# SN32F420 register map
Vendor: SONiX Technology Co., Ltd.; Series: SN32F420; File version: 1.00
CPU: CM0 r0p0, little endian, no MPU, no FPU, 2 interrupt priority bits
Registers are 32-bit, read-write, reset 0x0 unless marked. A register's access mark holds for its fields unless they carry their own. Offsets are from the block's base; [hi:lo] are bit positions; {n}, {i} and the like mark numbered series.

## SN_SYS1 — System Control Registers 1
Base 0x4005E000
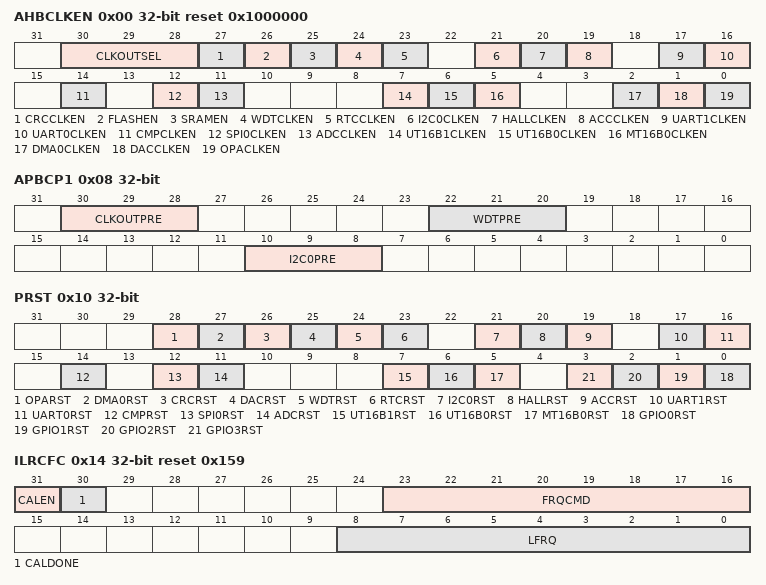
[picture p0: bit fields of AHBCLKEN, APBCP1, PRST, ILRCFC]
0x00 AHBCLKEN reset 0x1000000 — Offset:0x00 AHB Clock Enable register
  [30:28] CLKOUTSEL — Clock output source selection
    0=000b (Disable); 1=001b (ILRC); 4=100b (HCLK); 5=101b (IHRC); 7=111b (PLL output)
  [27] CRCCLKEN — Enable AHB clock for CRC
    0=Disable CRC clock; 1=Enable CRC clock
  [26] FLASHEN — Enable Flash clock during sleep mode
    0=Disable Flash clock during sleep mode; 1=Enable Flash clock during sleep mode
  [25] SRAMEN — Enable SRAM clock during sleep mode
    0=Disable SRAM clock during sleep mode; 1=Enable SRAM clock during sleep mode
  [24] WDTCLKEN ro — Enable AHB clock for WDT
    1=Enable WDT clock
  [23] RTCCLKEN — Enable AHB clock for RTC
    0=Disable RTC clock; 1=Enable RTC clock
  [21] I2C0CLKEN — Enable AHB clock for I2C0
    0=Disable I2C0 clock; 1=Enable I2C0 clock
  [20] HALLCLKEN — Enable AHB clock for HALL
    0=Disable HALL clock; 1=Enable HALL clock
  [19] ACCCLKEN — Enable AHB clock for ACC
    0=Disable ACC clock; 1=Enable ACC clock
  [17] UART1CLKEN — Enable AHB clock for UART1
    0=Disable UART1 clock; 1=Enable UART1 clock
  [16] UART0CLKEN — Enable AHB clock for UART0
    0=Disable UART0 clock; 1=Enable UART0 clock
  [14] CMPCLKEN — Enable AHB clock for CMP
    0=Disable CMP clock; 1=Enable CMP clock
  [12] SPI0CLKEN — Enable AHB clock for SPI0
    0=Disable SPI0 clock; 1=Enable SPI0 clock
  [11] ADCCLKEN — Enable AHB clock for ADC
    0=Disable ADC clock; 1=Enable ADC clock
  [7] UT16B1CLKEN — Enable AHB clock for UT16B1
    0=Disable UT16B1 clock; 1=Enable UT16B1 clock
  [6] UT16B0CLKEN — Enable AHB clock for UT16B0
    0=Disable UT16B0 clock; 1=Enable UT16B0 clock
  [5] MT16B0CLKEN — Enable AHB clock for MT16B0
    0=Disable MT16B0 clock; 1=Enable MT16B0 clock
  [2] DMA0CLKEN — Enable AHB clock for DMA0
    0=Disable DMA0 clock; 1=Enable DMA0 clock
  [1] DACCLKEN — Enable AHB clock for DAC
    0=Disable DAC clock; 1=Enable DAC clock
  [0] OPACLKEN — Enable AHB clock for OPA
    0=Disable OPA clock; 1=Enable OPA clock
0x08 APBCP1 — Offset:0x08 APB Clock Prescale register 1
  [30:28] CLKOUTPRE — CLKOUT APB clock source prescaler
    0=000b (FCLKOUT/1); 1=001b (FCLKOUT/2); 2=010b (FCLKOUT/4); 3=011b (FCLKOUT/8); 4=100b (FCLKOUT/16); 5=101b (FCLKOUT/32); 6=110b (FCLKOUT/64); 7=111b (FCLKOUT/128)
  [22:20] WDTPRE — WDT APB clock source prescaler
    0=000b (WDT_PCLK = WDT clock source / 1); 1=001b (WDT_PCLK = WDT clock source / 2); 2=010b (WDT_PCLK = WDT clock source / 4); 3=011b (WDT_PCLK = WDT clock source / 8); 4=100b (WDT_PCLK = WDT clock source / 16); 5=101b (WDT_PCLK = WDT clock source / 32)
  [10:8] I2C0PRE — I2C0 APB clock source prescaler
    0=000b (HCLK/1); 1=001b (HCLK/2); 2=010b (HCLK/4); 3=011b (HCLK/8); 4=100b (HCLK/16)
0x10 PRST wo — Offset:0x10 Peripheral Reset register
  [28] OPARST — OPA Reset
    0=No (No effect); 1=Reset OPA
  [27] DMA0RST — DMA0 Reset
    0=No (No effect); 1=Reset DMA0
  [26] CRCRST — CRC Reset
    0=No (No effect); 1=Reset CRC
  [25] DACRST — DAC Reset
    0=No (No effect); 1=Reset DAC
  [24] WDTRST — WDT Reset
    0=No (No effect); 1=Reset WDT
  [23] RTCRST — RTC Reset
    0=No (No effect); 1=Reset RTC
  [21] I2C0RST — I2C0 Reset
    0=No (No effect); 1=Reset I2C0
  [20] HALLRST — HALL Reset
    0=No (No effect); 1=Reset HALL
  [19] ACCRST — ACC Reset
    0=No (No effect); 1=Reset ACC
  [17] UART1RST — UART1 Reset
    0=No (No effect); 1=Reset UART1
  [16] UART0RST — UART0 Reset
    0=No (No effect); 1=Reset UART0
  [14] CMPRST — CMP Reset
    0=No (No effect); 1=Reset CMP
  [12] SPI0RST — SPI0 Reset
    0=No (No effect); 1=Reset SPI0
  [11] ADCRST — ADC Reset
    0=No (No effect); 1=Reset ADC
  [7] UT16B1RST — UT16B1 Reset
    0=No (No effect); 1=Reset UT16B1
  [6] UT16B0RST — UT16B0 Reset
    0=No (No effect); 1=Reset UT16B0
  [5] MT16B0RST — MT16B0 Reset
    0=No (No effect); 1=Reset MT16B0
  [n] GPIO{n}RST (n=0..3) — GPIO{n} Reset
    0=No (No effect); 1=Reset GPIO{n}
0x14 ILRCFC reset 0x159 — Offset:0x14 ILRC Frequency Calibration register
  [31] CALEN — Auto-calibration function enable
    0=Disable calibration function; 1=Enable ILRC calibration function
  [30] CALDONE — Calibration done
    0=No (No done); 1=Done (Calibration Done)
  [23:16] FRQCMD wo — Frequency calibration command
    75=ILRC auto-trim (Execute ILRC auto-trim function); 180=Load ILRC trim value
  [8:0] LFRQ — ILRC trim value
